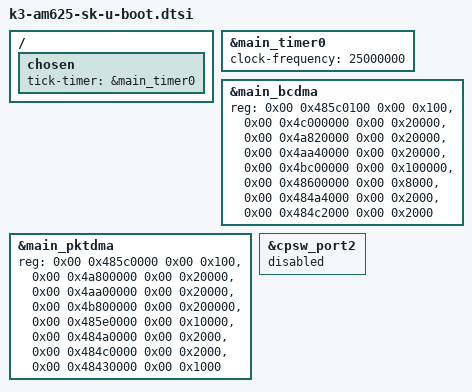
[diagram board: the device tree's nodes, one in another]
// SPDX-License-Identifier: GPL-2.0
/*
 * Common AM625 SK dts file for SPLs
 * Copyright (C) 2021-2022 Texas Instruments Incorporated - https://www.ti.com/
 */

#include "k3-am625-sk-binman.dtsi"

/ {
	chosen {
		tick-timer = &main_timer0;
	};
};

&main_timer0 {
	clock-frequency = <25000000>;
};

&main_bcdma {
	reg = <0x00 0x485c0100 0x00 0x100>,
	      <0x00 0x4c000000 0x00 0x20000>,
	      <0x00 0x4a820000 0x00 0x20000>,
	      <0x00 0x4aa40000 0x00 0x20000>,
	      <0x00 0x4bc00000 0x00 0x100000>,
	      <0x00 0x48600000 0x00 0x8000>,
	      <0x00 0x484a4000 0x00 0x2000>,
	      <0x00 0x484c2000 0x00 0x2000>;
	reg-names = "gcfg", "bchanrt", "rchanrt", "tchanrt",
		    "ringrt" , "cfg", "tchan", "rchan";
};

&main_pktdma {
	reg = <0x00 0x485c0000 0x00 0x100>,
	      <0x00 0x4a800000 0x00 0x20000>,
	      <0x00 0x4aa00000 0x00 0x20000>,
	      <0x00 0x4b800000 0x00 0x200000>,
	      <0x00 0x485e0000 0x00 0x10000>,
	      <0x00 0x484a0000 0x00 0x2000>,
	      <0x00 0x484c0000 0x00 0x2000>,
	      <0x00 0x48430000 0x00 0x1000>;
	reg-names = "gcfg", "rchanrt", "tchanrt", "ringrt",
		    "cfg", "tchan", "rchan", "rflow";
	bootph-all;
};

&cpsw_port2 {
	status = "disabled";
};
